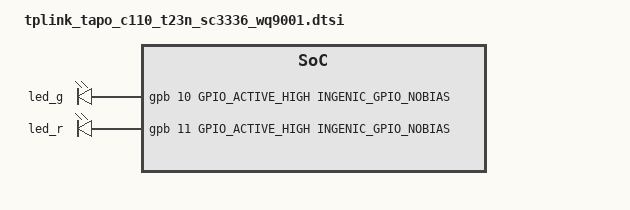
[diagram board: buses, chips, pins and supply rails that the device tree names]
// TP-Link Tapo C110 v3 (T23N, SC3336, WQ9001) per-board GPIO definitions.
// Injected into the kernel 4.4+ device tree; ignored on 3.10.

#include <dt-bindings/gpio/gpio.h>
#include <dt-bindings/pinctrl/ingenic-pinctrl.h>

/ {
	gpio-leds {
		compatible = "gpio-leds";

		led_g {
			label = "led_g";
			gpios = <&gpb 10 GPIO_ACTIVE_HIGH INGENIC_GPIO_NOBIAS>;
			default-state = "off";
		};

		led_r {
			label = "led_r";
			gpios = <&gpb 11 GPIO_ACTIVE_HIGH INGENIC_GPIO_NOBIAS>;
			default-state = "off";
		};
	};
};
